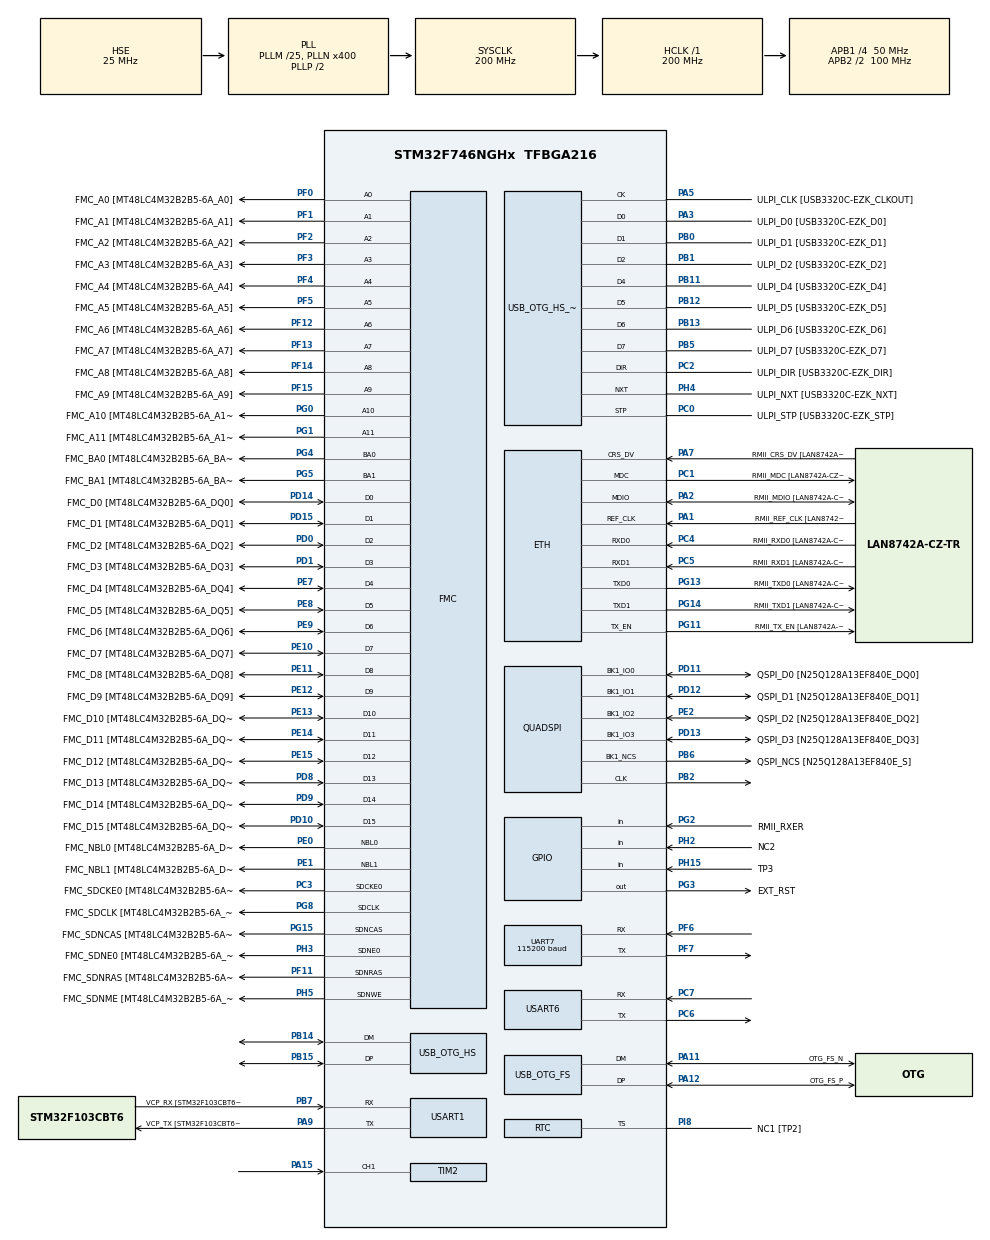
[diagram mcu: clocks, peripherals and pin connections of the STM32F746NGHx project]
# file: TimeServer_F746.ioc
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PD12.GPIO_Label=QSPI_D1 [N25Q128A13EF840E_DQ1]
FMC.SDClockPeriod2=FMC_SDRAM_CLOCK_PERIOD_2
FMC.SDClockPeriod1=FMC_SDRAM_CLOCK_PERIOD_2
SH.FMC_A0.0=FMC_A0,12b-sda1
PH15.GPIO_Label=TP3
NVIC.TIM6_DAC_IRQn=true\:0\:0\:false\:false\:true\:false\:false\:true
PG8.Signal=FMC_SDCLK
PG0.Signal=FMC_A10
Dma.USART6_RX.4.PeriphBurst=DMA_PBURST_SINGLE
SH.FMC_D5_DA5.0=FMC_D5,sd-16b-d1
Dma.UART7_RX.5.PeriphBurst=DMA_PBURST_SINGLE
Dma.UART7_TX.1.FIFOThreshold=DMA_FIFO_THRESHOLD_FULL
SH.FMC_D9_DA9.0=FMC_D9,sd-16b-d1
FREERTOS.configENABLE_FPU=1
Dma.USART1_TX.3.FIFOMode=DMA_FIFOMODE_DISABLE
PG15.GPIO_Label=FMC_SDNCAS [MT48LC4M32B2B5-6A_CAS]
PF7.Signal=UART7_TX
RCC.PLL48CLockSelection=RCC_CLK48SOURCE_PLLSAIP
SH.FMC_SDNWE.0=FMC_SDNWE,12b-sda1
SH.FMC_D11_DA11.0=FMC_D11,sd-16b-d1
RCC.APB2TimFreq_Value=200000000
PB6.Signal=QUADSPI_BK1_NCS
PC7.Signal=USART6_RX
PD0.Signal=FMC_D2_DA2
PD8.Signal=FMC_D13_DA13
USART6.VirtualMode-Asynchronous=VM_ASYNC
PE1.Signal=FMC_NBL1
PF1.GPIO_Label=FMC_A1 [MT48LC4M32B2B5-6A_A1]
PD1.GPIO_Label=FMC_D3 [MT48LC4M32B2B5-6A_DQ3]
PB12.GPIO_Label=ULPI_D5 [USB3320C-EZK_D5]
Dma.USART6_RX.4.Instance=DMA2_Stream1
PG14.Mode=RMII
FMC.SelfRefreshTime1=4
PF12.GPIO_Label=FMC_A6 [MT48LC4M32B2B5-6A_A6]
PC4.GPIO_Label=RMII_RXD0 [LAN8742A-CZ-TR_RXD0]
PE9.Signal=FMC_D6_DA6
SH.FMC_A2.0=FMC_A2,12b-sda1
PB14.Mode=Device_Only_FS
PB1.GPIO_Label=ULPI_D2 [USB3320C-EZK_D2]
PG4.GPIO_Label=FMC_BA0 [MT48LC4M32B2B5-6A_BA0]
Dma.UART7_TX.1.PeriphInc=DMA_PINC_DISABLE
ETH.PHY_Name=LAN8742A_PHY_ADDRESS
SH.FMC_D1_DA1.0=FMC_D1,sd-16b-d1
Dma.USART1_TX.3.Instance=DMA2_Stream7
Mcu.Package=TFBGA216
PB1.Signal=USB_OTG_HS_ULPI_D2
NVIC.TimeBase=TIM6_DAC_IRQn
PD12.Signal=QUADSPI_BK1_IO1
NVIC.TimeBaseIP=TIM6
VP_RTC_VS_RTC_Calendar.Mode=RTC_Calendar
PE12.GPIO_Label=FMC_D9 [MT48LC4M32B2B5-6A_DQ9]
FMC.WriteRecoveryTime1=3
RCC.APB2CLKDivider=RCC_HCLK_DIV2
RCC.APB1TimFreq_Value=100000000
PC14/OSC32_IN.GPIO_Label=RCC_OSC32_IN
FMC.RowCycleDelay2=7
FMC.RowCycleDelay1=7
PB13.Mode=Host_HS
PD15.Signal=FMC_D1_DA1
Dma.UART7_RX.5.PeriphInc=DMA_PINC_DISABLE
PA5.Mode=Host_HS
Dma.UART7_RX.5.MemDataAlignment=DMA_MDATAALIGN_BYTE
SH.FMC_A4.0=FMC_A4,12b-sda1
FREERTOS.Tasks01=defaultTask,24,4096,StartDefaultTask,Default,NULL,Dynamic,NULL,NULL
PG5.Signal=FMC_A15_BA1
SH.FMC_D10_DA10.0=FMC_D10,sd-16b-d1
PC2.Signal=USB_OTG_HS_ULPI_DIR
USB_OTG_HS.VirtualMode-Device_Only_FS=Device_Only_FS
RCC.PLLSAIRDiv=RCC_PLLSAIDIVR_8
PD10.Signal=FMC_D15_DA15
Dma.UART7_RX.5.Instance=DMA1_Stream3
PA3.Mode=Host_HS
PI8.GPIO_Label=NC1 [TP2]
Dma.USART1_RX.2.Mode=DMA_NORMAL
PE8.GPIO_Label=FMC_D5 [MT48LC4M32B2B5-6A_DQ5]
Dma.UART7_RX.5.FIFOMode=DMA_FIFOMODE_ENABLE
NVIC.DMA2_Stream6_IRQn=true\:5\:0\:false\:false\:true\:true\:false\:true
PB14.Signal=USB_OTG_HS_DM
PA5.Signal=USB_OTG_HS_ULPI_CK
FREERTOS.configUSE_POSIX_ERRNO=1
PE1.GPIO_Label=FMC_NBL1 [MT48LC4M32B2B5-6A_DQM1]
Dma.USART1_RX.2.Priority=DMA_PRIORITY_LOW
FMC.ReadBurst1=FMC_SDRAM_RBURST_ENABLE
SH.FMC_A6.0=FMC_A6,12b-sda1
FMC.ReadBurst2=FMC_SDRAM_RBURST_ENABLE
PE14.Signal=FMC_D11_DA11
PF4.GPIO_Label=FMC_A4 [MT48LC4M32B2B5-6A_A4]
PA1.GPIO_Label=RMII_REF_CLK [LAN8742A-CZ-TR_REFCLK0]
PF13.Signal=FMC_A7
ETH.MediaInterface=ETH_MEDIA_INTERFACE_RMII
PA5.GPIO_Label=ULPI_CLK [USB3320C-EZK_CLKOUT]
PC12.GPIO_Label=SDMMC_CK
ProjectManager.HeapSize=0x200
Dma.UART7_TX.1.MemInc=DMA_MINC_ENABLE
PB1.Mode=Host_HS
FREERTOS.configUSE_RECURSIVE_MUTEXES=1
NVIC.PriorityGroup=NVIC_PRIORITYGROUP_4
PF0.GPIO_Label=FMC_A0 [MT48LC4M32B2B5-6A_A0]
Dma.USART6_TX.0.Priority=DMA_PRIORITY_LOW
PC15/OSC32_OUT.Signal=RCC_OSC32_OUT
PF4.Signal=FMC_A4
PD2.Signal=SDMMC1_CMD
PC1.Mode=RMII
Mcu.Family=STM32F7
STMicroelectronics.X-CUBE-TOUCHGFX.4.14.0.ApplicationCcGraphicsJjApplication=TouchGFXOoGenerator
NVIC.OTG_HS_IRQn=true\:5\:0\:false\:false\:true\:true\:false\:true
SH.FMC_A8.0=FMC_A8,12b-sda1
PC15/OSC32_OUT.GPIO_Label=RCC_OSC32_OUT
TIM2.Channel-Input_Capture1_from_TI1=TIM_CHANNEL_1
SH.FMC_D14_DA14.0=FMC_D14,sd-16b-d1
PG2.Signal=GPIO_Input
PE11.GPIO_Label=FMC_D8 [MT48LC4M32B2B5-6A_DQ8]
PD0.GPIO_Label=FMC_D2 [MT48LC4M32B2B5-6A_DQ2]
PA11.Mode=Device_Only
PC14/OSC32_IN.Mode=LSE-External-Oscillator
SH.FMC_A14_BA0.0=FMC_BA0,FourSdramBanks1
SH.FMC_A11.0=FMC_A11,12b-sda1
PB13.GPIO_Label=ULPI_D6 [USB3320C-EZK_D6]
PG5.GPIO_Label=FMC_BA1 [MT48LC4M32B2B5-6A_BA1]
PB15.Signal=USB_OTG_HS_DP
VP_RTC_VS_RTC_Alarm_B_Intern.Mode=Alarm B
PG11.Signal=ETH_TX_EN
PG15.Signal=FMC_SDNCAS
PD13.Signal=QUADSPI_BK1_IO3
ETH.PHY_CONFIG_DELAY=0xfff
SH.FMC_NBL1.0=FMC_NBL1,Sd2ByteEnable1
PA9.GPIO_Mode=GPIO_MODE_AF_PP
RCC.HSE_VALUE=25000000
FMC.ExitSelfRefreshDelay1=7
PA14.Mode=Serial_Wire
PF11.Signal=FMC_SDNRAS
Dma.USART1_TX.3.PeriphInc=DMA_PINC_DISABLE
PC11.GPIO_Label=SDMMC_D3
PB5.Mode=Host_HS
PB7.Signal=USART1_RX
ETH.PHY_RESET_DELAY=0x00000FFF
PI8.Mode=Timestamp enabled - Input Enabled to TS
PB7.GPIO_Label=VCP_RX [STM32F103CBT6_PA2]
PD13.GPIO_Label=QSPI_D3 [N25Q128A13EF840E_DQ3]
PB12.Mode=Host_HS
NVIC.OTG_FS_IRQn=true\:5\:0\:false\:false\:true\:true\:true\:true
PA15.Signal=S_TIM2_CH1_ETR
USB_DEVICE.CLASS_NAME_HS=CDC
PG0.GPIO_Label=FMC_A10 [MT48LC4M32B2B5-6A_A10]
PB5.GPIO_Label=ULPI_D7 [USB3320C-EZK_D7]
Dma.Request2=USART1_RX
Dma.Request1=UART7_TX
Dma.Request4=USART6_RX
Dma.Request3=USART1_TX
Dma.Request5=UART7_RX
PG11.GPIO_Label=RMII_TX_EN [LAN8742A-CZ-TR_TXEN]
PC5.Signal=ETH_RXD1
PE7.Signal=FMC_D4_DA4
Dma.Request0=USART6_TX
PF3.GPIO_Label=FMC_A3 [MT48LC4M32B2B5-6A_A3]
PE2.GPIO_Label=QSPI_D2 [N25Q128A13EF840E_DQ2]
Dma.USART1_RX.2.MemDataAlignment=DMA_MDATAALIGN_BYTE
PG2.GPIO_Label=RMII_RXER
PA3.Signal=USB_OTG_HS_ULPI_D0
Dma.USART6_RX.4.MemDataAlignment=DMA_MDATAALIGN_BYTE
PD15.GPIO_Label=FMC_D1 [MT48LC4M32B2B5-6A_DQ1]
Dma.UART7_TX.1.Direction=DMA_MEMORY_TO_PERIPH
PC11.Signal=SDMMC1_D3
PC8.Signal=SDMMC1_D0
Dma.UART7_RX.5.Priority=DMA_PRIORITY_LOW
PC2.Mode=Host_HS
PE14.GPIO_Label=FMC_D11 [MT48LC4M32B2B5-6A_DQ11]
PD9.Signal=FMC_D14_DA14
PA9.GPIO_PuPd=GPIO_NOPULL
Dma.USART1_RX.2.PeriphInc=DMA_PINC_DISABLE
PA12.GPIO_Label=OTG_FS_P
PD8.GPIO_Label=FMC_D13 [MT48LC4M32B2B5-6A_DQ13]
PG8.GPIO_Label=FMC_SDCLK [MT48LC4M32B2B5-6A_CLK]
USART1.VirtualMode-Asynchronous=VM_ASYNC
PA13.Signal=SYS_JTMS-SWDIO
FREERTOS.configUSE_IDLE_HOOK=0
Dma.UART7_RX.5.Mode=DMA_NORMAL
PA9.Mode=Asynchronous
PF6.Signal=UART7_RX
SH.FMC_D13_DA13.0=FMC_D13,sd-16b-d1
Dma.USART1_RX.2.PeriphDataAlignment=DMA_PDATAALIGN_BYTE
Dma.USART1_TX.3.PeriphDataAlignment=DMA_PDATAALIGN_BYTE
RCC.USBFreq_Value=48000000
PD10.GPIO_Label=FMC_D15 [MT48LC4M32B2B5-6A_DQ15]
PA1.Signal=ETH_REF_CLK
board=STM32F746G-DISCO
RCC.VCOOutputFreq_Value=400000000
PH4.GPIO_Label=ULPI_NXT [USB3320C-EZK_NXT]
PB15.Mode=Device_Only_FS
PC1.GPIO_Label=RMII_MDC [LAN8742A-CZ-TR_MDC]
SH.FMC_D12_DA12.0=FMC_D12,sd-16b-d1
PF15.GPIO_Label=FMC_A9 [MT48LC4M32B2B5-6A_A9]
PF1.Signal=FMC_A1
PE0.Signal=FMC_NBL0
RTC.Alarm-Alarm\ A=RTC_ALARM_A
PE7.GPIO_Label=FMC_D4 [MT48LC4M32B2B5-6A_DQ4]
PE12.Signal=FMC_D9_DA9
RCC.SYSCLKFreq_VALUE=200000000
PB2.Mode=Single Bank 1
PD11.Mode=Single Bank 1
Dma.USART6_RX.4.FIFOThreshold=DMA_FIFO_THRESHOLD_FULL
RCC.HSI_VALUE=16000000
PH0/OSC_IN.GPIO_Label=OSC_25M [NZ2520SB-25.00M_OUT]
RCC.PLLQ=9
PH3.Signal=FMC_SDNE0
RCC.PLLM=25
RCC.PLLN=400
PA9.GPIO_Speed=GPIO_SPEED_FREQ_LOW
PA2.Mode=RMII
Dma.UART7_TX.1.MemBurst=DMA_MBURST_SINGLE
NVIC.DMA1_Stream3_IRQn=true\:5\:0\:false\:false\:true\:true\:false\:true
CORTEX_M7.CPU_DCache=Disabled
Dma.UART7_RX.5.Direction=DMA_PERIPH_TO_MEMORY
VP_CRC_VS_CRC.Mode=CRC_Activate
RCC.PLLI2SN=100
PB12.Signal=USB_OTG_HS_ULPI_D5
PA3.GPIO_Label=ULPI_D0 [USB3320C-EZK_D0]
NVIC.UART7_IRQn=true\:5\:0\:false\:false\:true\:true\:true\:true
SH.FMC_D7_DA7.0=FMC_D7,sd-16b-d1
RTC.Alarm_B-Alarm\ B=RTC_ALARM_B
VP_SYS_VS_tim6.Mode=TIM6
FMC.RCDDelay1=2
Dma.USART1_TX.3.MemInc=DMA_MINC_ENABLE
PG4.Signal=FMC_A14_BA0
PC12.Signal=SDMMC1_CK
PA14.GPIO_Label=SWCLK
Dma.USART1_RX.2.Instance=DMA2_Stream2
FMC.LoadToActiveDelay1=2
CORTEX_M7.PREFETCH_ENABLE=0
VP_RTC_VS_RTC_Activate.Mode=RTC_Enabled
PB6.GPIO_Label=QSPI_NCS [N25Q128A13EF840E_S]
PC5.Mode=RMII
PB13.Signal=USB_OTG_HS_ULPI_D6
PG13.Signal=ETH_TXD0
Dma.USART6_TX.0.Mode=DMA_NORMAL
RCC.SYSCLKSource=RCC_SYSCLKSOURCE_PLLCLK
SH.FMC_A15_BA1.0=FMC_BA1,FourSdramBanks1
Dma.UART7_RX.5.PeriphDataAlignment=DMA_PDATAALIGN_BYTE
PB7.GPIO_Mode=GPIO_MODE_AF_PP
Dma.USART6_TX.0.FIFOMode=DMA_FIFOMODE_DISABLE
PH5.Signal=FMC_SDNWE
Dma.USART6_TX.0.Instance=DMA2_Stream6
PE2.Mode=Single Bank 1
Dma.USART1_TX.3.Mode=DMA_NORMAL
PH1/OSC_OUT.Signal=RCC_OSC_OUT
PB6.Mode=Single Bank 1
PC3.Signal=FMC_SDCKE0
PB2.Signal=QUADSPI_CLK
PE2.Signal=QUADSPI_BK1_IO2
PF3.Signal=FMC_A3
PE10.Signal=FMC_D7_DA7
VP_TIM1_VS_ClockSourceINT.Mode=Internal
RCC.SDMMCClockSelection=RCC_SDMMC1CLKSOURCE_CLK48
SH.FMC_A1.0=FMC_A1,12b-sda1
PH2.Signal=GPIO_Input
NVIC.DMA2_Stream2_IRQn=true\:5\:0\:false\:false\:true\:true\:false\:true
SH.FMC_SDCLK.0=FMC_SDCLK,12b-sda1
PF14.Signal=FMC_A8
NVIC.USART1_IRQn=true\:5\:0\:false\:false\:true\:true\:true\:true
PE10.GPIO_Label=FMC_D7 [MT48LC4M32B2B5-6A_DQ7]
Dma.USART6_TX.0.MemDataAlignment=DMA_MDATAALIGN_BYTE
SH.FMC_D3_DA3.0=FMC_D3,sd-16b-d1
PC4.Mode=RMII
PB7.GPIO_PuPd=GPIO_NOPULL
PH15.Signal=GPIO_Input
Dma.USART6_TX.0.MemInc=DMA_MINC_ENABLE
PD9.GPIO_Label=FMC_D14 [MT48LC4M32B2B5-6A_DQ14]
Dma.UART7_TX.1.Mode=DMA_NORMAL
PA9.GPIO_Label=VCP_TX [STM32F103CBT6_PA3]
FREERTOS.configCHECK_FOR_STACK_OVERFLOW=2
Dma.USART6_RX.4.Priority=DMA_PRIORITY_LOW
PC6.Signal=USART6_TX
PB11.GPIO_Label=ULPI_D4 [USB3320C-EZK_D4]
PD1.Signal=FMC_D3_DA3
PA11.GPIO_Label=OTG_FS_N
PF14.GPIO_Label=FMC_A8 [MT48LC4M32B2B5-6A_A8]
NVIC.DMA2_Stream1_IRQn=true\:5\:0\:false\:false\:true\:true\:false\:true
PC0.Signal=USB_OTG_HS_ULPI_STP
RCC.APB1CLKDivider=RCC_HCLK_DIV4
PF13.GPIO_Label=FMC_A7 [MT48LC4M32B2B5-6A_A7]
PG13.GPIO_Label=RMII_TXD0 [LAN8742A-CZ-TR_TXD0]
Dma.USART6_RX.4.MemBurst=DMA_MBURST_SINGLE
SH.FMC_A3.0=FMC_A3,12b-sda1
FMC.CASLatency1=FMC_SDRAM_CAS_LATENCY_3
PB11.Mode=Host_HS
SH.FMC_D15_DA15.0=FMC_D15,sd-16b-d1
PC6.Mode=Asynchronous
PA9.Signal=USART1_TX
PE9.GPIO_Label=FMC_D6 [MT48LC4M32B2B5-6A_DQ6]
PA1.Mode=RMII
Dma.USART1_RX.2.Direction=DMA_PERIPH_TO_MEMORY
Dma.UART7_TX.1.FIFOMode=DMA_FIFOMODE_ENABLE
PE15.Signal=FMC_D12_DA12
PE8.Signal=FMC_D5_DA5
Dma.USART6_TX.0.PeriphInc=DMA_PINC_DISABLE
PG14.GPIO_Label=RMII_TXD1 [LAN8742A-CZ-TR_TXD1]
PA13.Mode=Serial_Wire
SH.FMC_SDNCAS.0=FMC_SDNCAS,12b-sda1
Dma.USART1_RX.2.MemInc=DMA_MINC_ENABLE
PH4.Mode=Host_HS
Dma.USART1_TX.3.Priority=DMA_PRIORITY_LOW
PB5.Signal=USB_OTG_HS_ULPI_D7
PD12.Mode=Single Bank 1
PE13.GPIO_Label=FMC_D10 [MT48LC4M32B2B5-6A_DQ10]
FREERTOS.configUSE_COUNTING_SEMAPHORES=1
Dma.USART6_RX.4.Direction=DMA_PERIPH_TO_MEMORY
PD11.Signal=QUADSPI_BK1_IO0
SH.FMC_A5.0=FMC_A5,12b-sda1
PG11.Mode=RMII
PA11.Signal=USB_OTG_FS_DM
SH.S_TIM2_CH1_ETR.0=TIM2_CH1,Input_Capture1_from_TI1
PF6.Mode=Asynchronous
UART7.BaudRate=115200
PC3.GPIO_Label=FMC_SDCKE0 [MT48LC4M32B2B5-6A_CKE]
PG3.GPIO_Label=EXT_RST
PB0.Signal=USB_OTG_HS_ULPI_D1
PC1.Signal=ETH_MDC
PH2.GPIO_Label=NC2
PD2.GPIO_Label=SDMMC_CMD
Dma.USART6_TX.0.PeriphDataAlignment=DMA_PDATAALIGN_BYTE
PC3.Mode=SdramChipSelect1_1
VP_USB_DEVICE_VS_USB_DEVICE_CDC_HS.Mode=CDC_HS
RCC.CortexFreq_Value=200000000
Dma.USART1_TX.3.MemDataAlignment=DMA_MDATAALIGN_BYTE
PC10.Signal=SDMMC1_D2
Dma.USART1_TX.3.Direction=DMA_MEMORY_TO_PERIPH
SH.FMC_NBL0.0=FMC_NBL0,Sd2ByteEnable1
PC0.GPIO_Label=ULPI_STP [USB3320C-EZK_STP]
SH.FMC_D6_DA6.0=FMC_D6,sd-16b-d1
PB0.GPIO_Label=ULPI_D1 [USB3320C-EZK_D1]
PH5.GPIO_Label=FMC_SDNME [MT48LC4M32B2B5-6A_WE]
PB11.Signal=USB_OTG_HS_ULPI_D4
VP_RTC_VS_RTC_Alarm_A_Intern.Mode=Alarm A
Dma.UART7_TX.1.Instance=DMA1_Stream1
ProjectManager.StackSize=0x400
VP_FREERTOS_VS_CMSIS_V2.Mode=CMSIS_V2
PH3.Mode=SdramChipSelect1_1
SH.FMC_A7.0=FMC_A7,12b-sda1
PA12.Signal=USB_OTG_FS_DP
Dma.USART6_TX.0.Direction=DMA_MEMORY_TO_PERIPH
PH0/OSC_IN.Mode=HSE-External-Oscillator
PD11.GPIO_Label=QSPI_D0 [N25Q128A13EF840E_DQ0]
RCC.HCLKFreq_Value=200000000
Dma.UART7_TX.1.PeriphDataAlignment=DMA_PDATAALIGN_BYTE
PF11.GPIO_Label=FMC_SDNRAS [MT48LC4M32B2B5-6A_RAS]
PF12.Signal=FMC_A6
FREERTOS.configUSE_MALLOC_FAILED_HOOK=1
Dma.UART7_RX.5.MemInc=DMA_MINC_ENABLE
USB_DEVICE.VirtualMode-CDC_HS=Cdc
SH.FMC_A10.0=FMC_A10,12b-sda1
RCC.AHBFreq_Value=200000000
SH.FMC_D8_DA8.0=FMC_D8,sd-16b-d1
Dma.USART6_RX.4.Mode=DMA_NORMAL
FMC.RPDelay2=2
FMC.RPDelay1=2
PI8.Signal=RTC_TS
SH.FMC_D2_DA2.0=FMC_D2,sd-16b-d1
PE13.Signal=FMC_D10_DA10
PG13.Mode=RMII
SH.FMC_SDNRAS.0=FMC_SDNRAS,12b-sda1
PH1/OSC_OUT.Mode=HSE-External-Oscillator
FREERTOS.configTOTAL_HEAP_SIZE=32768
Dma.USART6_RX.4.PeriphInc=DMA_PINC_DISABLE
NVIC.DMA2_Stream7_IRQn=true\:5\:0\:false\:false\:true\:true\:false\:true
SH.FMC_D0_DA0.0=FMC_D0,sd-16b-d1
PC14/OSC32_IN.Signal=RCC_OSC32_IN
PA2.GPIO_Label=RMII_MDIO [LAN8742A-CZ-TR_MDIO]
PF5.GPIO_Label=FMC_A5 [MT48LC4M32B2B5-6A_A5]
USB_OTG_FS.VirtualMode=Device_Only
SH.FMC_A9.0=FMC_A9,12b-sda1
SH.FMC_D4_DA4.0=FMC_D4,sd-16b-d1
PE0.GPIO_Label=FMC_NBL0 [MT48LC4M32B2B5-6A_DQM0]
RCC.PLLSAIN=384
PH3.GPIO_Label=FMC_SDNE0 [MT48LC4M32B2B5-6A_CS]
PF5.Signal=FMC_A5
RCC.PLLSAIP=RCC_PLLSAIP_DIV8
RCC.PLLSAIR=5
USB_DEVICE.VirtualModeHS=Cdc_HS
Dma.USART6_RX.4.MemInc=DMA_MINC_ENABLE
PF0.Signal=FMC_A0
PC2.GPIO_Label=ULPI_DIR [USB3320C-EZK_DIR]
PB7.GPIO_Speed=GPIO_SPEED_FREQ_LOW
CORTEX_M7.CPU_ICache=Disabled
Dma.UART7_TX.1.MemDataAlignment=DMA_MDATAALIGN_BYTE
PA7.Mode=RMII
PC10.GPIO_Label=SDMMC_D2
PG3.Signal=GPIO_Output
PG1.Signal=FMC_A11
Dma.UART7_TX.1.PeriphBurst=DMA_PBURST_SINGLE
PC4.Signal=ETH_RXD0
Dma.USART6_RX.4.PeriphDataAlignment=DMA_PDATAALIGN_BYTE
Dma.USART6_RX.4.FIFOMode=DMA_FIFOMODE_ENABLE
NVIC.DMA1_Stream1_IRQn=true\:5\:0\:false\:false\:true\:true\:false\:true
FREERTOS.configUSE_APPLICATION_TASK_TAG=1
ETH.PhyAddress=0
PC0.Mode=Host_HS
NVIC.USART6_IRQn=true\:5\:0\:false\:false\:true\:true\:true\:true
PF7.Mode=Asynchronous
PE15.GPIO_Label=FMC_D12 [MT48LC4M32B2B5-6A_DQ12]
PH4.Signal=USB_OTG_HS_ULPI_NXT
ProjectManager.TargetToolchain=SW4STM32
Dma.UART7_RX.5.FIFOThreshold=DMA_FIFO_THRESHOLD_FULL
PD13.Mode=Single Bank 1
PF2.Signal=FMC_A2
PE11.Signal=FMC_D8_DA8
PG14.Signal=ETH_TXD1
PB0.Mode=Host_HS
Dma.UART7_TX.1.Priority=DMA_PRIORITY_LOW
Dma.USART1_RX.2.FIFOMode=DMA_FIFOMODE_DISABLE
PG1.GPIO_Label=FMC_A11 [MT48LC4M32B2B5-6A_A11]
Dma.UART7_RX.5.MemBurst=DMA_MBURST_SINGLE
PH0/OSC_IN.Signal=RCC_OSC_IN
RCC.APB2Freq_Value=100000000
VP_TIM2_VS_ClockSourceINT.Mode=Internal
PF15.Signal=FMC_A9
PD14.GPIO_Label=FMC_D0 [MT48LC4M32B2B5-6A_DQ0]
Mcu.Name=STM32F746NGHx
PA13.GPIO_Label=SWDIO
PA2.Signal=ETH_MDIO
PD14.Signal=FMC_D0_DA0
PA7.GPIO_Label=RMII_CRS_DV [LAN8742A-CZ-TR_CRS_DV]
PA12.Mode=Device_Only
PC5.GPIO_Label=RMII_RXD1 [LAN8742A-CZ-TR_RXD1]
PC15/OSC32_OUT.Mode=LSE-External-Oscillator
PB7.Mode=Asynchronous
PA14.Signal=SYS_JTCK-SWCLK
PC9.Signal=SDMMC1_D1
PC7.Mode=Asynchronous
RCC.APB1Freq_Value=50000000
PA7.Signal=ETH_CRS_DV
PF2.GPIO_Label=FMC_A2 [MT48LC4M32B2B5-6A_A2]

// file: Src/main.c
/* USER CODE BEGIN Header */
/**
  ******************************************************************************
  * @file           : main.c
  * @brief          : Main program body
  ******************************************************************************
  * @attention
  *
  * <h2><center>&copy; Copyright (c) 2020 STMicroelectronics.
  * All rights reserved.</center></h2>
  *
  * This software component is licensed by ST under Ultimate Liberty license
  * SLA0044, the "License"; You may not use this file except in compliance with
  * the License. You may obtain a copy of the License at:
  *                             www.st.com/SLA0044
  *
  ******************************************************************************
  */
/* USER CODE END Header */

#include "main.h"
#include "cmsis_os.h"
#include "usb_device.h"

/* USER CODE BEGIN Includes */
#include <stdio.h>
/* USER CODE END Includes */

CRC_HandleTypeDef hcrc;

ETH_HandleTypeDef heth;

QSPI_HandleTypeDef hqspi;

RTC_HandleTypeDef hrtc;

TIM_HandleTypeDef htim1;
TIM_HandleTypeDef htim2;

UART_HandleTypeDef huart7;
UART_HandleTypeDef huart1;
UART_HandleTypeDef huart6;
DMA_HandleTypeDef hdma_uart7_tx;
DMA_HandleTypeDef hdma_uart7_rx;
DMA_HandleTypeDef hdma_usart1_rx;
DMA_HandleTypeDef hdma_usart1_tx;
DMA_HandleTypeDef hdma_usart6_tx;
DMA_HandleTypeDef hdma_usart6_rx;

PCD_HandleTypeDef hpcd_USB_OTG_FS;

SDRAM_HandleTypeDef hsdram1;

/* Definitions for defaultTask */
osThreadId_t defaultTaskHandle;
const osThreadAttr_t defaultTask_attributes = {
  .name = "defaultTask",
  .priority = (osPriority_t) osPriorityNormal,
  .stack_size = 4096 * 4
};
/* USER CODE BEGIN PV */
struct CircBuf pcNmeaRx_cBuf;
struct CircBuf gpsNmeaRx_cBuf;
#if(0)
struct CircBuf pcBinrRx_cBuf;
struct CircBuf gpsBinrRx_cBuf;
#endif
UART_HandleTypeDef * pcNmea_uartHandle = &huart7;
UART_HandleTypeDef * gpsNmea_uartHandle = &huart6;
UART_HandleTypeDef * debugUart	= &huart1;
#if(0)
UART_HandleTypeDef * pcBinrUart;
UART_HandleTypeDef * gpsBinrUart;
#endif

/* Flags */
bool pcNmea_uartHandle_isSending = false;
bool gpsNmea_uartHandle_isSending = false;
bool debugUart_isSending = false;

osSemaphoreId_t gpsNmeaRx_semaHandle;
osSemaphoreId_t pcNmeaRx_semaHandle;
#if(0)
osSemaphoreId_t gpsBinrRx_semaHandle;
osSemaphoreId_t pcBinrRx_semaHandle;
#endif

struct Node * gpsNmea_msgList;
struct Node * pcNmea_msgList;

/* USER CODE END PV */

void SystemClock_Config(void);
static void MX_GPIO_Init(void);
static void MX_DMA_Init(void);
static void MX_CRC_Init(void);
static void MX_ETH_Init(void);
static void MX_FMC_Init(void);
static void MX_QUADSPI_Init(void);
static void MX_RTC_Init(void);
static void MX_TIM1_Init(void);
static void MX_TIM2_Init(void);
static void MX_UART7_Init(void);
static void MX_USART1_UART_Init(void);
static void MX_USART6_UART_Init(void);
static void MX_USB_OTG_FS_PCD_Init(void);
void StartDefaultTask(void *argument);

/* USER CODE BEGIN PFP */
osThreadId_t pcNmeaRx_thrdHandle;
osThreadId_t gpsNmeaRx_thrdHandle;
void pcNmeaRx_thread(void * argument);
void gpsNmeaRx_thread(void * argument);

/* USER CODE END PFP */

int main(void)
{

  /* MCU Configuration--------------------------------------------------------*/

  /* Reset of all peripherals, Initializes the Flash interface and the Systick. */
  HAL_Init();

  /* Configure the system clock */
  SystemClock_Config();

  /* Initialize all configured peripherals */
  MX_GPIO_Init();
  MX_DMA_Init();
  MX_CRC_Init();
  MX_ETH_Init();
  MX_FMC_Init();
  MX_QUADSPI_Init();
  MX_RTC_Init();
  MX_TIM1_Init();
  MX_TIM2_Init();
  MX_UART7_Init();
  MX_USART1_UART_Init();
  MX_USART6_UART_Init();
  MX_USB_OTG_FS_PCD_Init();

  /* Init scheduler */
  osKernelInitialize();

  /* USER CODE BEGIN RTOS_MUTEX */

	/* Heap model initialized above.
	* So I assume it is safe to ask for heap memory here. */
  	int bufNum = 0;
	gpsNmea_msgList = initList(NMEA_MSG_MAX_SIZE);
	if(!gpsNmea_msgList) return EXIT_FAILURE;
	for(bufNum = 1 /*exclude head node*/; \
		bufNum < NMEA_MSG_LIST_LEN; bufNum++)
	{
		addNode(gpsNmea_msgList);
	}
	pcNmea_msgList = initList(NMEA_MSG_MAX_SIZE);
	if(!pcNmea_msgList) return EXIT_FAILURE;
	for(bufNum = 1 /*exclude head node*/; \
		bufNum < NMEA_MSG_LIST_LEN; bufNum++)
	{
		addNode(pcNmea_msgList);
	}

  /* add mutexes, ... */
  /* USER CODE END RTOS_MUTEX */

  /* USER CODE BEGIN RTOS_SEMAPHORES */
  /* add semaphores, ... */
  gpsNmeaRx_semaHandle = osSemaphoreNew(1, 0, NULL);
  pcNmeaRx_semaHandle = osSemaphoreNew(1, 0, NULL);

  /* USER CODE END RTOS_SEMAPHORES */

  /* Create the thread(s) */
  /* creation of defaultTask */
  defaultTaskHandle = osThreadNew(StartDefaultTask, NULL, &defaultTask_attributes);

  /* USER CODE BEGIN RTOS_THREADS */
  /* add threads, ... */
  pcNmeaRx_thrdHandle = osThreadNew(pcNmeaRx_thread, NULL, NULL);
  gpsNmeaRx_thrdHandle = osThreadNew(gpsNmeaRx_thread, NULL, NULL);

  //extern const osThreadAttr_t pcNMEAmsgExtrr_thrdAtts;
  //pcNMEAmsgExtrr_thrdHandle = osThreadNew(pcNMEAmsgExtrr, NULL, &pcNMEAmsgExtrr_thrdAtts);
  /* USER CODE END RTOS_THREADS */

  /* Start scheduler */
  osKernelStart();

  /* We should never get here as control is now taken by the scheduler */
  /* Infinite loop */
  while (1)
  {

  }
}

void SystemClock_Config(void)
{
  RCC_OscInitTypeDef RCC_OscInitStruct = {0};
  RCC_ClkInitTypeDef RCC_ClkInitStruct = {0};
  RCC_PeriphCLKInitTypeDef PeriphClkInitStruct = {0};

  /** Configure LSE Drive Capability
  */
  HAL_PWR_EnableBkUpAccess();
  /** Configure the main internal regulator output voltage
  */
  __HAL_RCC_PWR_CLK_ENABLE();
  __HAL_PWR_VOLTAGESCALING_CONFIG(PWR_REGULATOR_VOLTAGE_SCALE1);
  /** Initializes the CPU, AHB and APB busses clocks
  */
  RCC_OscInitStruct.OscillatorType = RCC_OSCILLATORTYPE_LSI|RCC_OSCILLATORTYPE_HSE;
  RCC_OscInitStruct.HSEState = RCC_HSE_ON;
  RCC_OscInitStruct.LSIState = RCC_LSI_ON;
  RCC_OscInitStruct.PLL.PLLState = RCC_PLL_ON;
  RCC_OscInitStruct.PLL.PLLSource = RCC_PLLSOURCE_HSE;
  RCC_OscInitStruct.PLL.PLLM = 25;
  RCC_OscInitStruct.PLL.PLLN = 400;
  RCC_OscInitStruct.PLL.PLLP = RCC_PLLP_DIV2;
  RCC_OscInitStruct.PLL.PLLQ = 9;
  if (HAL_RCC_OscConfig(&RCC_OscInitStruct) != HAL_OK)
  {
    Error_Handler();
  }
  /** Activate the Over-Drive mode
  */
  if (HAL_PWREx_EnableOverDrive() != HAL_OK)
  {
    Error_Handler();
  }
  /** Initializes the CPU, AHB and APB busses clocks
  */
  RCC_ClkInitStruct.ClockType = RCC_CLOCKTYPE_HCLK|RCC_CLOCKTYPE_SYSCLK
                              |RCC_CLOCKTYPE_PCLK1|RCC_CLOCKTYPE_PCLK2;
  RCC_ClkInitStruct.SYSCLKSource = RCC_SYSCLKSOURCE_PLLCLK;
  RCC_ClkInitStruct.AHBCLKDivider = RCC_SYSCLK_DIV1;
  RCC_ClkInitStruct.APB1CLKDivider = RCC_HCLK_DIV4;
  RCC_ClkInitStruct.APB2CLKDivider = RCC_HCLK_DIV2;

  if (HAL_RCC_ClockConfig(&RCC_ClkInitStruct, FLASH_LATENCY_6) != HAL_OK)
  {
    Error_Handler();
  }
  PeriphClkInitStruct.PeriphClockSelection = RCC_PERIPHCLK_RTC|RCC_PERIPHCLK_USART1
                              |RCC_PERIPHCLK_USART6|RCC_PERIPHCLK_UART7
                              |RCC_PERIPHCLK_CLK48;
  PeriphClkInitStruct.PLLSAI.PLLSAIN = 384;
  PeriphClkInitStruct.PLLSAI.PLLSAIR = 5;
  PeriphClkInitStruct.PLLSAI.PLLSAIQ = 2;
  PeriphClkInitStruct.PLLSAI.PLLSAIP = RCC_PLLSAIP_DIV8;
  PeriphClkInitStruct.PLLSAIDivQ = 1;
  PeriphClkInitStruct.PLLSAIDivR = RCC_PLLSAIDIVR_8;
  PeriphClkInitStruct.RTCClockSelection = RCC_RTCCLKSOURCE_LSI;
  PeriphClkInitStruct.Usart1ClockSelection = RCC_USART1CLKSOURCE_PCLK2;
  PeriphClkInitStruct.Usart6ClockSelection = RCC_USART6CLKSOURCE_PCLK2;
  PeriphClkInitStruct.Uart7ClockSelection = RCC_UART7CLKSOURCE_PCLK1;
  PeriphClkInitStruct.Clk48ClockSelection = RCC_CLK48SOURCE_PLLSAIP;
  if (HAL_RCCEx_PeriphCLKConfig(&PeriphClkInitStruct) != HAL_OK)
  {
    Error_Handler();
  }
}

static void MX_CRC_Init(void)
{

  hcrc.Instance = CRC;
  hcrc.Init.DefaultPolynomialUse = DEFAULT_POLYNOMIAL_ENABLE;
  hcrc.Init.DefaultInitValueUse = DEFAULT_INIT_VALUE_ENABLE;
  hcrc.Init.InputDataInversionMode = CRC_INPUTDATA_INVERSION_NONE;
  hcrc.Init.OutputDataInversionMode = CRC_OUTPUTDATA_INVERSION_DISABLE;
  hcrc.InputDataFormat = CRC_INPUTDATA_FORMAT_BYTES;
  if (HAL_CRC_Init(&hcrc) != HAL_OK)
  {
    Error_Handler();
  }

}

static void MX_ETH_Init(void)
{

  heth.Instance = ETH;
  heth.Init.AutoNegotiation = ETH_AUTONEGOTIATION_ENABLE;
  heth.Init.PhyAddress = LAN8742A_PHY_ADDRESS;
  heth.Init.MACAddr[0] =   0x00;
  heth.Init.MACAddr[1] =   0x80;
  heth.Init.MACAddr[2] =   0xE1;
  heth.Init.MACAddr[3] =   0x00;
  heth.Init.MACAddr[4] =   0x00;
  heth.Init.MACAddr[5] =   0x00;
  heth.Init.RxMode = ETH_RXPOLLING_MODE;
  heth.Init.ChecksumMode = ETH_CHECKSUM_BY_HARDWARE;
  heth.Init.MediaInterface = ETH_MEDIA_INTERFACE_RMII;

  if (HAL_ETH_Init(&heth) != HAL_OK)
  {
    Error_Handler();
  }

}

static void MX_QUADSPI_Init(void)
{

  /* QUADSPI parameter configuration*/
  hqspi.Instance = QUADSPI;
  hqspi.Init.ClockPrescaler = 255;
  hqspi.Init.FifoThreshold = 1;
  hqspi.Init.SampleShifting = QSPI_SAMPLE_SHIFTING_NONE;
  hqspi.Init.FlashSize = 1;
  hqspi.Init.ChipSelectHighTime = QSPI_CS_HIGH_TIME_1_CYCLE;
  hqspi.Init.ClockMode = QSPI_CLOCK_MODE_0;
  hqspi.Init.FlashID = QSPI_FLASH_ID_1;
  hqspi.Init.DualFlash = QSPI_DUALFLASH_DISABLE;
  if (HAL_QSPI_Init(&hqspi) != HAL_OK)
  {
    Error_Handler();
  }

}

static void MX_RTC_Init(void)
{

  RTC_TimeTypeDef sTime = {0};
  RTC_DateTypeDef sDate = {0};
  RTC_AlarmTypeDef sAlarm = {0};

  /** Initialize RTC Only
  */
  hrtc.Instance = RTC;
  hrtc.Init.HourFormat = RTC_HOURFORMAT_24;
  hrtc.Init.AsynchPrediv = 127;
  hrtc.Init.SynchPrediv = 255;
  hrtc.Init.OutPut = RTC_OUTPUT_DISABLE;
  hrtc.Init.OutPutPolarity = RTC_OUTPUT_POLARITY_HIGH;
  hrtc.Init.OutPutType = RTC_OUTPUT_TYPE_OPENDRAIN;
  if (HAL_RTC_Init(&hrtc) != HAL_OK)
  {
    Error_Handler();
  }

  /** Initialize RTC and set the Time and Date
  */
  sTime.Hours = 0x0;
  sTime.Minutes = 0x0;
  sTime.Seconds = 0x0;
  sTime.DayLightSaving = RTC_DAYLIGHTSAVING_NONE;
  sTime.StoreOperation = RTC_STOREOPERATION_RESET;
  if (HAL_RTC_SetTime(&hrtc, &sTime, RTC_FORMAT_BCD) != HAL_OK)
  {
    Error_Handler();
  }
  sDate.WeekDay = RTC_WEEKDAY_MONDAY;
  sDate.Month = RTC_MONTH_JANUARY;
  sDate.Date = 0x1;
  sDate.Year = 0x0;
  if (HAL_RTC_SetDate(&hrtc, &sDate, RTC_FORMAT_BCD) != HAL_OK)
  {
    Error_Handler();
  }
  /** Enable the Alarm A
  */
  sAlarm.AlarmTime.Hours = 0x0;
  sAlarm.AlarmTime.Minutes = 0x0;
  sAlarm.AlarmTime.Seconds = 0x0;
  sAlarm.AlarmTime.SubSeconds = 0x0;
  sAlarm.AlarmTime.DayLightSaving = RTC_DAYLIGHTSAVING_NONE;
  sAlarm.AlarmTime.StoreOperation = RTC_STOREOPERATION_RESET;
  sAlarm.AlarmMask = RTC_ALARMMASK_NONE;
  sAlarm.AlarmSubSecondMask = RTC_ALARMSUBSECONDMASK_ALL;
  sAlarm.AlarmDateWeekDaySel = RTC_ALARMDATEWEEKDAYSEL_DATE;
  sAlarm.AlarmDateWeekDay = 0x1;
  sAlarm.Alarm = RTC_ALARM_A;
  if (HAL_RTC_SetAlarm(&hrtc, &sAlarm, RTC_FORMAT_BCD) != HAL_OK)
  {
    Error_Handler();
  }
  /** Enable the Alarm B
  */
  sAlarm.AlarmDateWeekDay = 0x1;
  sAlarm.Alarm = RTC_ALARM_B;
  if (HAL_RTC_SetAlarm(&hrtc, &sAlarm, RTC_FORMAT_BCD) != HAL_OK)
  {
    Error_Handler();
  }
  /** Enable the TimeStamp
  */
  if (HAL_RTCEx_SetTimeStamp(&hrtc, RTC_TIMESTAMPEDGE_RISING, RTC_TIMESTAMPPIN_POS1) != HAL_OK)
  {
    Error_Handler();
  }

}

static void MX_TIM1_Init(void)
{

  TIM_ClockConfigTypeDef sClockSourceConfig = {0};
  TIM_MasterConfigTypeDef sMasterConfig = {0};

  htim1.Instance = TIM1;
  htim1.Init.Prescaler = 0;
  htim1.Init.CounterMode = TIM_COUNTERMODE_UP;
  htim1.Init.Period = 0;
  htim1.Init.ClockDivision = TIM_CLOCKDIVISION_DIV1;
  htim1.Init.RepetitionCounter = 0;
  htim1.Init.AutoReloadPreload = TIM_AUTORELOAD_PRELOAD_DISABLE;
  if (HAL_TIM_Base_Init(&htim1) != HAL_OK)
  {
    Error_Handler();
  }
  sClockSourceConfig.ClockSource = TIM_CLOCKSOURCE_INTERNAL;
  if (HAL_TIM_ConfigClockSource(&htim1, &sClockSourceConfig) != HAL_OK)
  {
    Error_Handler();
  }
  sMasterConfig.MasterOutputTrigger = TIM_TRGO_RESET;
  sMasterConfig.MasterOutputTrigger2 = TIM_TRGO2_RESET;
  sMasterConfig.MasterSlaveMode = TIM_MASTERSLAVEMODE_DISABLE;
  if (HAL_TIMEx_MasterConfigSynchronization(&htim1, &sMasterConfig) != HAL_OK)
  {
    Error_Handler();
  }

}

static void MX_TIM2_Init(void)
{

  TIM_ClockConfigTypeDef sClockSourceConfig = {0};
  TIM_MasterConfigTypeDef sMasterConfig = {0};
  TIM_IC_InitTypeDef sConfigIC = {0};

  htim2.Instance = TIM2;
  htim2.Init.Prescaler = 0;
  htim2.Init.CounterMode = TIM_COUNTERMODE_UP;
  htim2.Init.Period = 0;
  htim2.Init.ClockDivision = TIM_CLOCKDIVISION_DIV1;
  htim2.Init.AutoReloadPreload = TIM_AUTORELOAD_PRELOAD_DISABLE;
  if (HAL_TIM_Base_Init(&htim2) != HAL_OK)
  {
    Error_Handler();
  }
  sClockSourceConfig.ClockSource = TIM_CLOCKSOURCE_INTERNAL;
  if (HAL_TIM_ConfigClockSource(&htim2, &sClockSourceConfig) != HAL_OK)
  {
    Error_Handler();
  }
  if (HAL_TIM_IC_Init(&htim2) != HAL_OK)
  {
    Error_Handler();
  }
  sMasterConfig.MasterOutputTrigger = TIM_TRGO_RESET;
  sMasterConfig.MasterSlaveMode = TIM_MASTERSLAVEMODE_DISABLE;
  if (HAL_TIMEx_MasterConfigSynchronization(&htim2, &sMasterConfig) != HAL_OK)
  {
    Error_Handler();
  }
  sConfigIC.ICPolarity = TIM_INPUTCHANNELPOLARITY_RISING;
  sConfigIC.ICSelection = TIM_ICSELECTION_DIRECTTI;
  sConfigIC.ICPrescaler = TIM_ICPSC_DIV1;
  sConfigIC.ICFilter = 0;
  if (HAL_TIM_IC_ConfigChannel(&htim2, &sConfigIC, TIM_CHANNEL_1) != HAL_OK)
  {
    Error_Handler();
  }

}

static void MX_UART7_Init(void)
{

  huart7.Instance = UART7;
  huart7.Init.BaudRate = 115200;
  huart7.Init.WordLength = UART_WORDLENGTH_8B;
  huart7.Init.StopBits = UART_STOPBITS_1;
  huart7.Init.Parity = UART_PARITY_NONE;
  huart7.Init.Mode = UART_MODE_TX_RX;
  huart7.Init.HwFlowCtl = UART_HWCONTROL_NONE;
  huart7.Init.OverSampling = UART_OVERSAMPLING_16;
  huart7.Init.OneBitSampling = UART_ONE_BIT_SAMPLE_DISABLE;
  huart7.AdvancedInit.AdvFeatureInit = UART_ADVFEATURE_NO_INIT;
  if (HAL_UART_Init(&huart7) != HAL_OK)
  {
    Error_Handler();
  }

}

static void MX_USART1_UART_Init(void)
{

  huart1.Instance = USART1;
  huart1.Init.BaudRate = 115200;
  huart1.Init.WordLength = UART_WORDLENGTH_8B;
  huart1.Init.StopBits = UART_STOPBITS_1;
  huart1.Init.Parity = UART_PARITY_NONE;
  huart1.Init.Mode = UART_MODE_TX_RX;
  huart1.Init.HwFlowCtl = UART_HWCONTROL_NONE;
  huart1.Init.OverSampling = UART_OVERSAMPLING_16;
  huart1.Init.OneBitSampling = UART_ONE_BIT_SAMPLE_DISABLE;
  huart1.AdvancedInit.AdvFeatureInit = UART_ADVFEATURE_NO_INIT;
  if (HAL_UART_Init(&huart1) != HAL_OK)
  {
    Error_Handler();
  }

}

static void MX_USART6_UART_Init(void)
{

  huart6.Instance = USART6;
  huart6.Init.BaudRate = 115200;
  huart6.Init.WordLength = UART_WORDLENGTH_8B;
  huart6.Init.StopBits = UART_STOPBITS_1;
  huart6.Init.Parity = UART_PARITY_NONE;
  huart6.Init.Mode = UART_MODE_TX_RX;
  huart6.Init.HwFlowCtl = UART_HWCONTROL_NONE;
  huart6.Init.OverSampling = UART_OVERSAMPLING_16;
  huart6.Init.OneBitSampling = UART_ONE_BIT_SAMPLE_DISABLE;
  huart6.AdvancedInit.AdvFeatureInit = UART_ADVFEATURE_NO_INIT;
  if (HAL_UART_Init(&huart6) != HAL_OK)
  {
    Error_Handler();
  }

}

static void MX_USB_OTG_FS_PCD_Init(void)
{

  hpcd_USB_OTG_FS.Instance = USB_OTG_FS;
  hpcd_USB_OTG_FS.Init.dev_endpoints = 6;
  hpcd_USB_OTG_FS.Init.speed = PCD_SPEED_FULL;
  hpcd_USB_OTG_FS.Init.dma_enable = DISABLE;
  hpcd_USB_OTG_FS.Init.phy_itface = PCD_PHY_EMBEDDED;
  hpcd_USB_OTG_FS.Init.Sof_enable = DISABLE;
  hpcd_USB_OTG_FS.Init.low_power_enable = DISABLE;
  hpcd_USB_OTG_FS.Init.lpm_enable = DISABLE;
  hpcd_USB_OTG_FS.Init.vbus_sensing_enable = DISABLE;
  hpcd_USB_OTG_FS.Init.use_dedicated_ep1 = DISABLE;
  if (HAL_PCD_Init(&hpcd_USB_OTG_FS) != HAL_OK)
  {
    Error_Handler();
  }

}

static void MX_DMA_Init(void)
{

  /* DMA controller clock enable */
  __HAL_RCC_DMA2_CLK_ENABLE();
  __HAL_RCC_DMA1_CLK_ENABLE();

  /* DMA interrupt init */
  /* DMA1_Stream1_IRQn interrupt configuration */
  HAL_NVIC_SetPriority(DMA1_Stream1_IRQn, 5, 0);
  HAL_NVIC_EnableIRQ(DMA1_Stream1_IRQn);
  /* DMA1_Stream3_IRQn interrupt configuration */
  HAL_NVIC_SetPriority(DMA1_Stream3_IRQn, 5, 0);
  HAL_NVIC_EnableIRQ(DMA1_Stream3_IRQn);
  /* DMA2_Stream1_IRQn interrupt configuration */
  HAL_NVIC_SetPriority(DMA2_Stream1_IRQn, 5, 0);
  HAL_NVIC_EnableIRQ(DMA2_Stream1_IRQn);
  /* DMA2_Stream2_IRQn interrupt configuration */
  HAL_NVIC_SetPriority(DMA2_Stream2_IRQn, 5, 0);
  HAL_NVIC_EnableIRQ(DMA2_Stream2_IRQn);
  /* DMA2_Stream6_IRQn interrupt configuration */
  HAL_NVIC_SetPriority(DMA2_Stream6_IRQn, 5, 0);
  HAL_NVIC_EnableIRQ(DMA2_Stream6_IRQn);
  /* DMA2_Stream7_IRQn interrupt configuration */
  HAL_NVIC_SetPriority(DMA2_Stream7_IRQn, 5, 0);
  HAL_NVIC_EnableIRQ(DMA2_Stream7_IRQn);

}

/* FMC initialization function */
static void MX_FMC_Init(void)
{

  FMC_SDRAM_TimingTypeDef SdramTiming = {0};

  /** Perform the SDRAM1 memory initialization sequence
  */
  hsdram1.Instance = FMC_SDRAM_DEVICE;
  /* hsdram1.Init */
  hsdram1.Init.SDBank = FMC_SDRAM_BANK1;
  hsdram1.Init.ColumnBitsNumber = FMC_SDRAM_COLUMN_BITS_NUM_8;
  hsdram1.Init.RowBitsNumber = FMC_SDRAM_ROW_BITS_NUM_12;
  hsdram1.Init.MemoryDataWidth = FMC_SDRAM_MEM_BUS_WIDTH_16;
  hsdram1.Init.InternalBankNumber = FMC_SDRAM_INTERN_BANKS_NUM_4;
  hsdram1.Init.CASLatency = FMC_SDRAM_CAS_LATENCY_3;
  hsdram1.Init.WriteProtection = FMC_SDRAM_WRITE_PROTECTION_DISABLE;
  hsdram1.Init.SDClockPeriod = FMC_SDRAM_CLOCK_PERIOD_2;
  hsdram1.Init.ReadBurst = FMC_SDRAM_RBURST_ENABLE;
  hsdram1.Init.ReadPipeDelay = FMC_SDRAM_RPIPE_DELAY_0;
  /* SdramTiming */
  SdramTiming.LoadToActiveDelay = 2;
  SdramTiming.ExitSelfRefreshDelay = 7;
  SdramTiming.SelfRefreshTime = 4;
  SdramTiming.RowCycleDelay = 7;
  SdramTiming.WriteRecoveryTime = 3;
  SdramTiming.RPDelay = 2;
  SdramTiming.RCDDelay = 2;

  if (HAL_SDRAM_Init(&hsdram1, &SdramTiming) != HAL_OK)
  {
    Error_Handler( );
  }

}

static void MX_GPIO_Init(void)
{
  GPIO_InitTypeDef GPIO_InitStruct = {0};

  /* GPIO Ports Clock Enable */
  __HAL_RCC_GPIOE_CLK_ENABLE();
  __HAL_RCC_GPIOG_CLK_ENABLE();
  __HAL_RCC_GPIOB_CLK_ENABLE();
  __HAL_RCC_GPIOC_CLK_ENABLE();
  __HAL_RCC_GPIOA_CLK_ENABLE();
  __HAL_RCC_GPIOD_CLK_ENABLE();
  __HAL_RCC_GPIOI_CLK_ENABLE();
  __HAL_RCC_GPIOF_CLK_ENABLE();
  __HAL_RCC_GPIOH_CLK_ENABLE();

  /*Configure GPIO pin Output Level */
  HAL_GPIO_WritePin(EXT_RST_GPIO_Port, EXT_RST_Pin, GPIO_PIN_RESET);

  /*Configure GPIO pins : SDMMC_CK_Pin SDMMC_D3_Pin SDMMC_D2_Pin PC9
                           PC8 */
  GPIO_InitStruct.Pin = SDMMC_CK_Pin|SDMMC_D3_Pin|SDMMC_D2_Pin|GPIO_PIN_9
                          |GPIO_PIN_8;
  GPIO_InitStruct.Mode = GPIO_MODE_AF_PP;
  GPIO_InitStruct.Pull = GPIO_NOPULL;
  GPIO_InitStruct.Speed = GPIO_SPEED_FREQ_VERY_HIGH;
  GPIO_InitStruct.Alternate = GPIO_AF12_SDMMC1;
  HAL_GPIO_Init(GPIOC, &GPIO_InitStruct);

  /*Configure GPIO pin : SDMMC_CMD_Pin */
  GPIO_InitStruct.Pin = SDMMC_CMD_Pin;
  GPIO_InitStruct.Mode = GPIO_MODE_AF_PP;
  GPIO_InitStruct.Pull = GPIO_NOPULL;
  GPIO_InitStruct.Speed = GPIO_SPEED_FREQ_VERY_HIGH;
  GPIO_InitStruct.Alternate = GPIO_AF12_SDMMC1;
  HAL_GPIO_Init(SDMMC_CMD_GPIO_Port, &GPIO_InitStruct);

  /*Configure GPIO pins : TP3_Pin NC2_Pin */
  GPIO_InitStruct.Pin = TP3_Pin|NC2_Pin;
  GPIO_InitStruct.Mode = GPIO_MODE_INPUT;
  GPIO_InitStruct.Pull = GPIO_NOPULL;
  HAL_GPIO_Init(GPIOH, &GPIO_InitStruct);

  /*Configure GPIO pin : EXT_RST_Pin */
  GPIO_InitStruct.Pin = EXT_RST_Pin;
  GPIO_InitStruct.Mode = GPIO_MODE_OUTPUT_PP;
  GPIO_InitStruct.Pull = GPIO_NOPULL;
  GPIO_InitStruct.Speed = GPIO_SPEED_FREQ_LOW;
  HAL_GPIO_Init(EXT_RST_GPIO_Port, &GPIO_InitStruct);

  /*Configure GPIO pin : RMII_RXER_Pin */
  GPIO_InitStruct.Pin = RMII_RXER_Pin;
  GPIO_InitStruct.Mode = GPIO_MODE_INPUT;
  GPIO_InitStruct.Pull = GPIO_NOPULL;
  HAL_GPIO_Init(RMII_RXER_GPIO_Port, &GPIO_InitStruct);

}

/* USER CODE BEGIN 4 */
void vApplicationMallocFailedHook( void )
{
    printf( "Allocation failed.\r\n" );
}
/**
  * @brief  Retargets the C library printf function to the USART.
  */
int _write(int fd, char * ptr, int len)
{
	HAL_UART_Transmit(&huart1, (uint8_t *)ptr, len, HAL_MAX_DELAY);
	return len;
}

//wrapper
void pcNmeaRx_thread(void *argument)
{
	/* Initialization */
	struct UartData uartData =
	{
		.uartHandle 	= pcNmea_uartHandle,
		.msgList 		= pcNmea_msgList,
		.rxSemaHandle 	= pcNmeaRx_semaHandle
	};
	/* Actual thread function */
	uartRxThread_func(&uartData);
}

//wrapper
void gpsNmeaRx_thread(void *argument)
{
	/* Initialization */
	struct UartData uartData =
	{
		.uartHandle 	= gpsNmea_uartHandle,
		.msgList 		= gpsNmea_msgList,
		.rxSemaHandle 	= gpsNmeaRx_semaHandle
	};
	/* Actual thread function */
	uartRxThread_func(&uartData);
}

/* USER CODE END 4 */

void StartDefaultTask(void *argument)
{
  /* init code for USB_DEVICE */
  MX_USB_DEVICE_Init();
  for(;;)
  {
    osDelay(1);
  }
}

 /**
  * @brief  Period elapsed callback in non blocking mode
  * @note   This function is called  when TIM6 interrupt took place, inside
  * HAL_TIM_IRQHandler(). It makes a direct call to HAL_IncTick() to increment
  * a global variable "uwTick" used as application time base.
  * @param  htim : TIM handle
  * @retval None
  */
void HAL_TIM_PeriodElapsedCallback(TIM_HandleTypeDef *htim)
{
  if (htim->Instance == TIM6) {
    HAL_IncTick();
  }
}

void Error_Handler(void)
{
}

/************************ (C) COPYRIGHT STMicroelectronics *****END OF FILE****/
